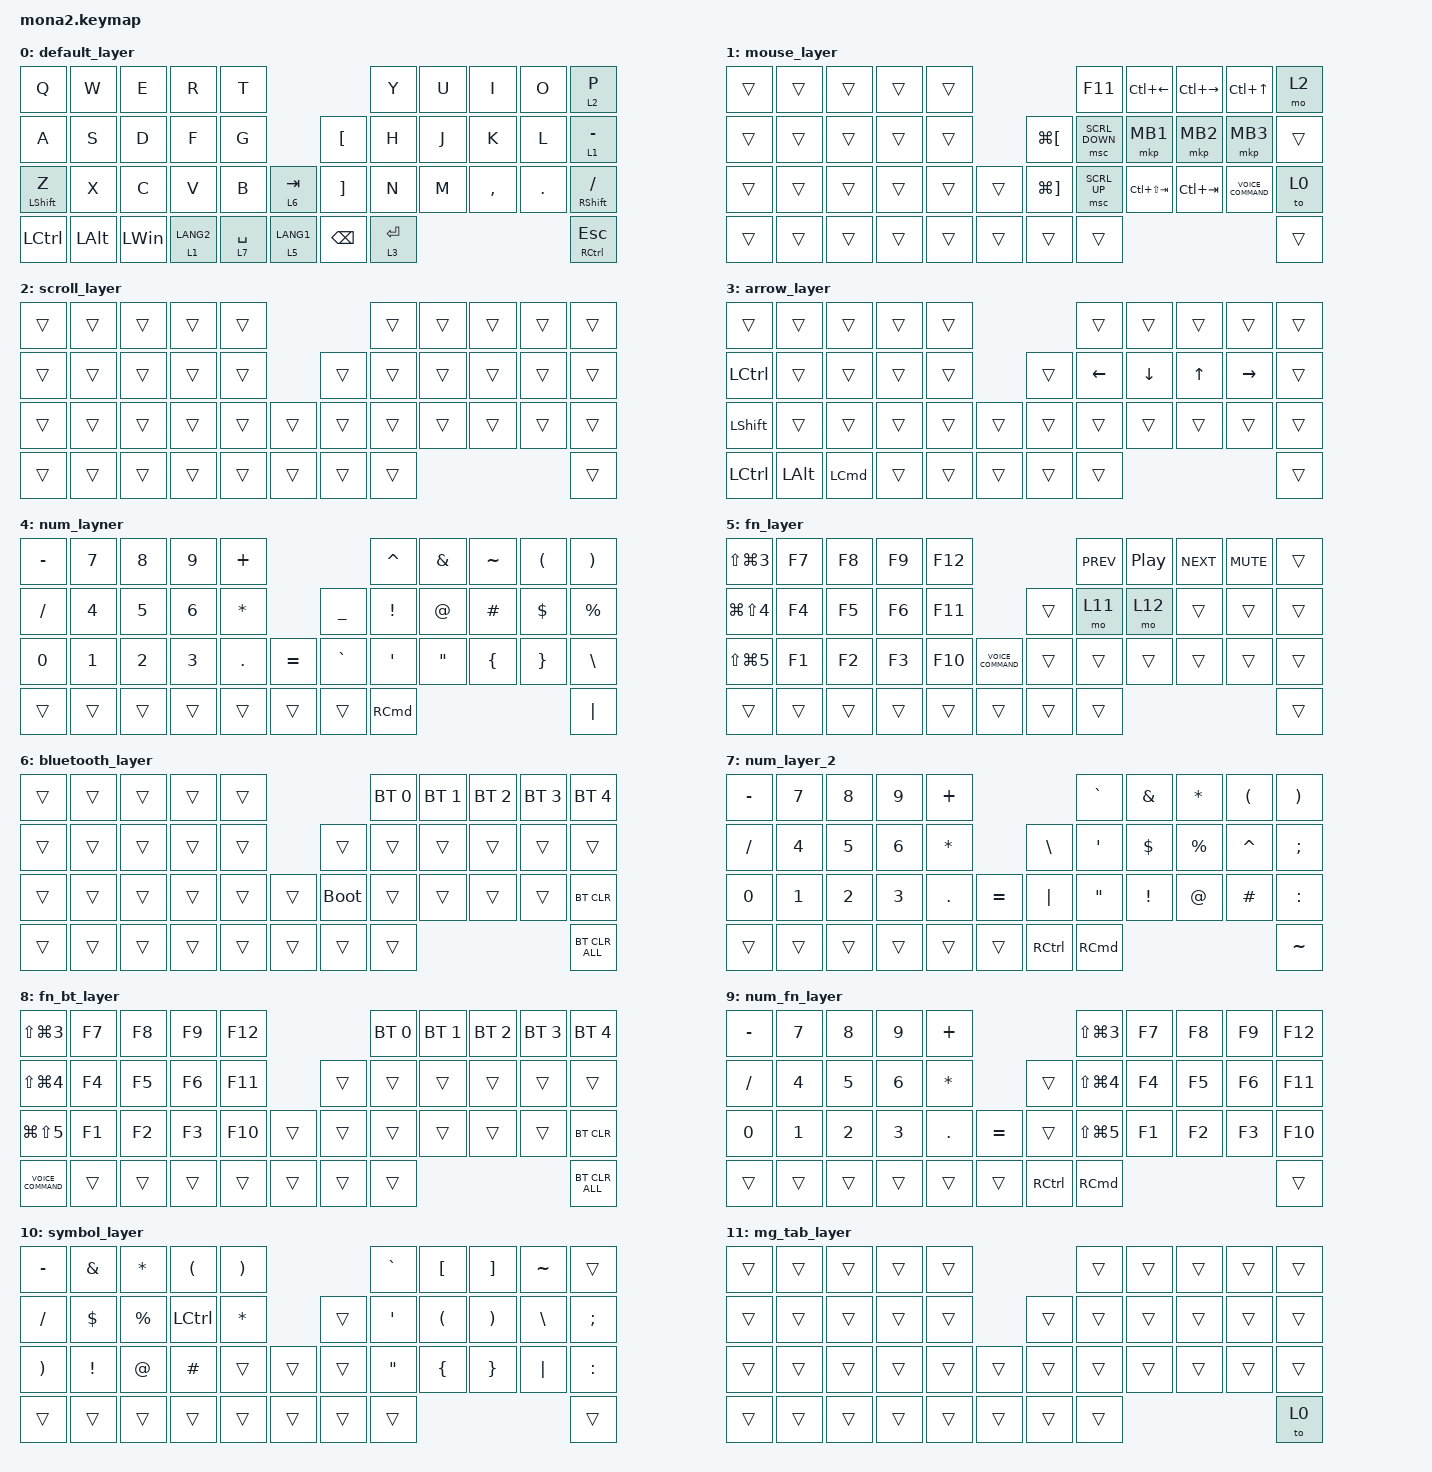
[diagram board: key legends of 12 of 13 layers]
#include <input/processors.dtsi>
#include <dt-bindings/zmk/input_transform.h>
#include <zephyr/dt-bindings/input/input-event-codes.h>
#include <behaviors.dtsi>
#include <dt-bindings/zmk/bt.h>
#include <dt-bindings/zmk/keys.h>
#include <dt-bindings/zmk/pointing.h>

#define ZMK_POINTING_DEFAULT_SCRL_VAL 100
#define MOUSE 5
#define SCROLL 6

&mt {
    flavor = "balanced";
    quick-tap-ms = <0>;
};

&lt {
    // layer/tapでタップしてもう一度押してホールドするとタップが連打されるまでの時間. default<300>ms

    quick-tap-ms = <0>;
    flavor = "balanced";
};

/ {
    combos {
        compatible = "zmk,combos";

        to_mouse_layer {
            bindings = <&to 1>;
            key-positions = <9 20>;
        };

        left-click {
            bindings = <&mkp LCLK>;
            key-positions = <17 18>;
        };

        right-click {
            bindings = <&mkp RCLK>;
            key-positions = <18 19>;
        };

        middle-click {
            bindings = <&mkp MCLK>;
            key-positions = <19 17>;
        };

        esc {
            bindings = <&kp ESCAPE>;
            key-positions = <0 1>;
        };

        tab {
            bindings = <&kp TAB>;
            key-positions = <12 13>;
        };

        shift-tab {
            bindings = <&kp LS(TAB)>;
            key-positions = <12 11>;
        };
    };

    macros {
        to_layer_0: to_layer_0 {
            compatible = "zmk,behavior-macro-one-param";
            #binding-cells = <1>;
            bindings = <&to 0 &macro_param_1to1 &kp MACRO_PLACEHOLDER>;
            label = "TO_LAYER_0";
        };

        test_pass: myPass {
            compatible = "zmk,behavior-macro";
            #binding-cells = <0>;
            bindings = <&none &kp A &kp B &kp C &kp D &kp E &kp F &kp G &kp H &kp I &kp J &kp K &kp L &kp M &kp N>;
            label = "MYPASS";
        };

        to_layer0_with_lang1: to_layer1_with_lang1 {
            compatible = "zmk,behavior-macro";
            #binding-cells = <0>;
            bindings = <&to 0 &kp LANG1>;
            label = "TO_LAYER1_WITH_LANG1";
        };

        to_layer0_with_lang2: new_macroto_layer0_with_lang2 {
            compatible = "zmk,behavior-macro";
            #binding-cells = <0>;
            bindings = <&to 0 &kp LANG2>;
            label = "NEW_MACROTO_LAYER0_WITH_LANG2";
        };

        to_layer0_with_command: to_layer0_with_command {
            compatible = "zmk,behavior-macro";
            #binding-cells = <0>;
            bindings =
                <&to 0>,
                <&macro_press>,
                <&kp LEFT_COMMAND>,
                <&macro_pause_for_release>,
                <&macro_release>,
                <&kp LEFT_COMMAND>;

            label = "TO_LAYER0_WITH_COMMAND";
        };

        to_layer0_with_alt: to_layer0_with_alt {
            compatible = "zmk,behavior-macro";
            #binding-cells = <0>;
            bindings =
                <&to 0>,
                <&macro_press>,
                <&kp LALT>,
                <&macro_pause_for_release>,
                <&macro_release>,
                <&kp LALT>;

            label = "TO_LAYER0_WITH_ALT";
        };

        to_layer0_with_ctrl: to_layer0_with_ctrl {
            compatible = "zmk,behavior-macro";
            #binding-cells = <0>;
            bindings =
                <&to 0>,
                <&macro_press>,
                <&kp LCTRL>,
                <&macro_pause_for_release>,
                <&macro_release>,
                <&kp LCTRL>;

            label = "TO_LAYER0_WITH_CTRL";
        };

        // Cmd+スクロールでmacOSのピンチズームを再現
        // 押している間ズームし続け、離すと止まる

        pinch_in: pinch_in_2 {
            compatible = "zmk,behavior-macro";
            #binding-cells = <0>;
            bindings =
                <&macro_press>,
                <&kp LEFT_COMMAND &msc SCRL_UP>,
                <&macro_pause_for_release>,
                <&macro_release>,
                <&kp LEFT_COMMAND &msc SCRL_UP>;

            label = "PINCH_IN_2";
        };

        pinch_out: pinch_out_2 {
            compatible = "zmk,behavior-macro";
            #binding-cells = <0>;
            bindings =
                <&macro_press>,
                <&kp LEFT_COMMAND &msc SCRL_DOWN>,
                <&macro_pause_for_release>,
                <&macro_release>,
                <&kp LEFT_COMMAND &msc SCRL_DOWN>;

            label = "PINCH_OUT_2";
        };
    };

    behaviors {
        lt_to_layer_0: lt_to_layer_0 {
            compatible = "zmk,behavior-hold-tap";
            label = "LAYER_TAP_TO_0";
            bindings = <&mo>, <&to_layer_0>;

            #binding-cells = <2>;
            tapping-term-ms = <200>;
        };

        scroll_up_down: mouse_wheel_up_down {
            compatible = "zmk,behavior-sensor-rotate";
            #sensor-binding-cells = <0>;
            bindings = <&msc SCRL_DOWN>, <&msc SCRL_UP>;

            tap-ms = <20>;
        };

        scroll_right_left: mouse_wheel_right_left {
            compatible = "zmk,behavior-sensor-rotate";
            #sensor-binding-cells = <0>;
            bindings = <&msc SCRL_LEFT>, <&msc SCRL_RIGHT>;

            tap-ms = <20>;
        };
    };

    keymap {
        compatible = "zmk,keymap";

        default_layer {
            bindings = <
&kp Q             &kp W         &kp E         &kp R        &kp T                                          &kp Y        &kp U  &kp I      &kp O    &lt 2 P
&kp A             &kp S         &kp D         &kp F        &kp G                       &kp LEFT_BRACKET   &kp H        &kp J  &kp K      &kp L    &lt 1 MINUS
&mt LEFT_SHIFT Z  &kp X         &kp C         &kp V        &kp B        &lt 6 TAB      &kp RIGHT_BRACKET  &kp N        &kp M  &kp COMMA  &kp DOT  &mt RIGHT_SHIFT SLASH
&kp LCTRL         &kp LEFT_ALT  &kp LEFT_WIN  &lt 1 LANG2  &lt 7 SPACE  &lt 5 LANG1    &kp BACKSPACE      &lt 3 ENTER                             &mt RIGHT_CONTROL ESCAPE
            >;

            sensor-bindings = <&scroll_up_down>;
        };

        mouse_layer {
            bindings = <
&trans  &trans  &trans  &trans  &trans                                   &kp F11         &kp LC(LEFT_ARROW)  &kp LC(RIGHT_ARROW)  &kp LC(UP_ARROW)     &mo 2
&trans  &trans  &trans  &trans  &trans            &kp LG(LEFT_BRACKET)   &msc SCRL_DOWN  &mkp MB1            &mkp MB2             &mkp MB3             &trans
&trans  &trans  &trans  &trans  &trans  &trans    &kp LG(RIGHT_BRACKET)  &msc SCRL_UP    &kp LC(LS(TAB))     &kp LC(TAB)          &kp C_VOICE_COMMAND  &to 0
&trans  &trans  &trans  &trans  &trans  &trans    &trans                 &trans                                                                        &trans
            >;

            sensor-bindings = <&scroll_up_down>;
        };

        scroll_layer {
            bindings = <
&trans  &trans  &trans  &trans  &trans                    &trans  &trans  &trans  &trans  &trans
&trans  &trans  &trans  &trans  &trans            &trans  &trans  &trans  &trans  &trans  &trans
&trans  &trans  &trans  &trans  &trans  &trans    &trans  &trans  &trans  &trans  &trans  &trans
&trans  &trans  &trans  &trans  &trans  &trans    &trans  &trans                          &trans
            >;

            sensor-bindings = <&scroll_up_down>;
        };

        arrow_layer {
            bindings = <
&trans            &trans        &trans            &trans  &trans                    &trans    &trans    &trans        &trans     &trans
&kp LCTRL         &trans        &trans            &trans  &trans            &trans  &kp LEFT  &kp DOWN  &kp UP_ARROW  &kp RIGHT  &trans
&kp LEFT_SHIFT    &trans        &trans            &trans  &trans  &trans    &trans  &trans    &trans    &trans        &trans     &trans
&kp LEFT_CONTROL  &kp LEFT_ALT  &kp LEFT_COMMAND  &trans  &trans  &trans    &trans  &trans                                       &trans
            >;

            sensor-bindings = <&inc_dec_kp C_BRI_DN C_BRI_UP>;
        };

        num_layner {
            bindings = <
&kp MINUS     &kp NUMBER_7  &kp NUMBER_8  &kp NUMBER_9  &kp PLUS                                   &kp CARET          &kp AMPERSAND      &kp TILDE       &kp LEFT_PARENTHESIS  &kp RIGHT_PARENTHESIS
&kp SLASH     &kp NUMBER_4  &kp NUMBER_5  &kp NUMBER_6  &kp ASTERISK               &kp UNDERSCORE  &kp EXCLAMATION    &kp AT_SIGN        &kp HASH        &kp DOLLAR            &kp PERCENT
&kp NUMBER_0  &kp NUMBER_1  &kp NUMBER_2  &kp NUMBER_3  &kp PERIOD    &kp EQUAL    &kp GRAVE       &kp SQT            &kp DOUBLE_QUOTES  &kp LEFT_BRACE  &kp RIGHT_BRACE       &kp BACKSLASH
&trans        &trans        &trans        &trans        &trans        &trans       &trans          &kp RIGHT_COMMAND                                                           &kp PIPE
            >;

            sensor-bindings = <&inc_dec_kp K_VOL_DN K_VOL_UP>;
        };

        fn_layer {
            bindings = <
&kp LS(LG(NUMBER_3))  &kp F7  &kp F8  &kp F9  &kp F12                                 &kp C_PREV  &kp C_PP  &kp C_NEXT  &kp C_MUTE  &trans
&kp LG(LS(NUMBER_4))  &kp F4  &kp F5  &kp F6  &kp F11                         &trans  &mo 11      &mo 12    &trans      &trans      &trans
&kp LS(LG(N5))        &kp F1  &kp F2  &kp F3  &kp F10  &kp C_VOICE_COMMAND    &trans  &trans      &trans    &trans      &trans      &trans
&trans                &trans  &trans  &trans  &trans   &trans                 &trans  &trans                                        &trans
            >;

            sensor-bindings = <&inc_dec_kp C_VOL_DN C_VOL_UP>;
        };

        bluetooth_layer {
            bindings = <
&trans  &trans  &trans  &trans  &trans                         &bt BT_SEL 0  &bt BT_SEL 1  &bt BT_SEL 2  &bt BT_SEL 3  &bt BT_SEL 4
&trans  &trans  &trans  &trans  &trans            &trans       &trans        &trans        &trans        &trans        &trans
&trans  &trans  &trans  &trans  &trans  &trans    &bootloader  &trans        &trans        &trans        &trans        &bt BT_CLR
&trans  &trans  &trans  &trans  &trans  &trans    &trans       &trans                                                  &bt BT_CLR_ALL
            >;

            sensor-bindings = <&scroll_up_down>;
        };

        num_layer_2 {
            bindings = <
&kp MINUS     &kp NUMBER_7  &kp NUMBER_8  &kp NUMBER_9  &kp PLUS                                  &kp GRAVE          &kp AMPERSAND    &kp ASTERISK  &kp LEFT_PARENTHESIS  &kp RIGHT_PARENTHESIS
&kp SLASH     &kp NUMBER_4  &kp NUMBER_5  &kp NUMBER_6  &kp ASTERISK               &kp BACKSLASH  &kp SINGLE_QUOTE   &kp DOLLAR       &kp PERCENT   &kp CARET             &kp SEMI
&kp NUMBER_0  &kp NUMBER_1  &kp NUMBER_2  &kp NUMBER_3  &kp PERIOD    &kp EQUAL    &kp PIPE       &kp DOUBLE_QUOTES  &kp EXCLAMATION  &kp AT_SIGN   &kp HASH              &kp COLON
&trans        &trans        &trans        &trans        &trans        &trans       &kp RCTRL      &kp RIGHT_COMMAND                                                       &kp TILDE
            >;

            sensor-bindings = <&inc_dec_kp K_VOL_DN K_VOL_UP>;
        };

        fn_bt_layer {
            bindings = <
&kp LS(LG(NUMBER_3))  &kp F7  &kp F8  &kp F9  &kp F12                    &bt BT_SEL 0  &bt BT_SEL 1  &bt BT_SEL 2  &bt BT_SEL 3  &bt BT_SEL 4
&kp LS(LG(NUMBER_4))  &kp F4  &kp F5  &kp F6  &kp F11            &trans  &trans        &trans        &trans        &trans        &trans
&kp LG(LS(N5))        &kp F1  &kp F2  &kp F3  &kp F10  &trans    &trans  &trans        &trans        &trans        &trans        &bt BT_CLR
&kp C_VOICE_COMMAND   &trans  &trans  &trans  &trans   &trans    &trans  &trans                                                  &bt BT_CLR_ALL
            >;

            sensor-bindings = <&inc_dec_kp C_VOL_DN C_VOL_UP>;
        };

        num_fn_layer {
            bindings = <
&kp MINUS     &kp NUMBER_7  &kp NUMBER_8  &kp NUMBER_9  &kp PLUS                              &kp LS(LG(NUMBER_3))  &kp F7  &kp F8  &kp F9  &kp F12
&kp SLASH     &kp NUMBER_4  &kp NUMBER_5  &kp NUMBER_6  &kp ASTERISK               &trans     &kp LS(LG(NUMBER_4))  &kp F4  &kp F5  &kp F6  &kp F11
&kp NUMBER_0  &kp NUMBER_1  &kp NUMBER_2  &kp NUMBER_3  &kp PERIOD    &kp EQUAL    &trans     &kp LS(LG(N5))        &kp F1  &kp F2  &kp F3  &kp F10
&trans        &trans        &trans        &trans        &trans        &trans       &kp RCTRL  &kp RCMD                                      &trans
            >;

            sensor-bindings = <&inc_dec_kp K_VOL_DN K_VOL_UP>;
        };

        symbol_layer {
            bindings = <
&kp MINUS              &kp AMPERSAND    &kp ASTERISK  &kp LEFT_PARENTHESIS  &kp RIGHT_PARENTHESIS                    &kp GRAVE          &kp LEFT_BRACKET      &kp RIGHT_BRACKET      &kp TILDE      &trans
&kp SLASH              &kp DOLLAR       &kp PERCENT   &kp LCTRL             &kp ASTERISK                     &trans  &kp SINGLE_QUOTE   &kp LEFT_PARENTHESIS  &kp RIGHT_PARENTHESIS  &kp BACKSLASH  &kp SEMI
&kp RIGHT_PARENTHESIS  &kp EXCLAMATION  &kp AT_SIGN   &kp HASH              &trans                 &trans    &trans  &kp DOUBLE_QUOTES  &kp LEFT_BRACE        &kp RIGHT_BRACE        &kp PIPE       &kp COLON
&trans                 &trans           &trans        &trans                &trans                 &trans    &trans  &trans                                                                         &trans
            >;

            sensor-bindings = <&inc_dec_kp K_VOL_DN K_VOL_UP>;
        };

        mg_tab_layer {
            bindings = <
&trans  &trans  &trans  &trans  &trans                    &trans  &trans  &trans  &trans  &trans
&trans  &trans  &trans  &trans  &trans            &trans  &trans  &trans  &trans  &trans  &trans
&trans  &trans  &trans  &trans  &trans  &trans    &trans  &trans  &trans  &trans  &trans  &trans
&trans  &trans  &trans  &trans  &trans  &trans    &trans  &trans                          &to 0
            >;

            sensor-bindings = <&scroll_up_down>;
        };

        mg_swipe_layer {
            bindings = <
&trans  &trans  &trans  &trans  &trans                    &trans  &trans  &trans  &trans  &trans
&trans  &trans  &trans  &trans  &trans            &trans  &trans  &trans  &trans  &trans  &trans
&trans  &trans  &trans  &trans  &trans  &trans    &trans  &trans  &trans  &trans  &trans  &trans
&trans  &trans  &trans  &trans  &trans  &trans    &trans  &trans                          &to 0
            >;

            sensor-bindings = <&scroll_up_down>;
        };
    };
};
